# AVR16DU28 device description
Architecture: AVR8X; Family: AVR
Registers are 8-bit, read-write, reset 0x0 unless marked. A register's access mark holds for its fields unless they carry their own. Offsets are from the block's base; [hi:lo] are bit positions; {n}, {i} and the like mark numbered series; 'fields as' and 'values as' point back to an identical list.

## RSTCTRL — Reset controller
Instances: RSTCTRL 0x0040
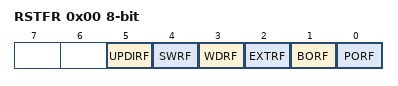
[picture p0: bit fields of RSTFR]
0x00 RSTFR — Reset Flags
  [5] UPDIRF — UPDI Reset flag
  [4] SWRF — Software Reset flag
  [3] WDRF — Watch dog Reset flag
  [2] EXTRF — External Reset flag
  [1] BORF — Brown out detector Reset flag
  [0] PORF — Power on Reset flag
0x01 SWRR — Software Reset
  [0] SWRST — Software reset enable

## RTC — Real-Time Counter
Instances: RTC 0x0140
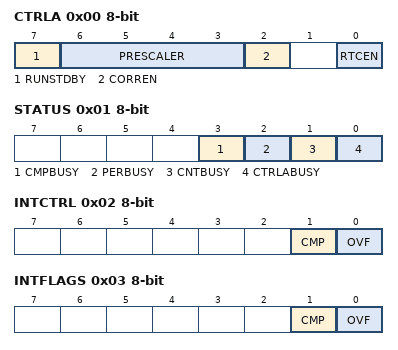
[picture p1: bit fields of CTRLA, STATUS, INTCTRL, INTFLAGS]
0x00 CTRLA — Control A
  [7] RUNSTDBY — Run In Standby
  [6:3] PRESCALER — Prescaling Factor
    0=DIV1 (RTC Clock / 1); 1=DIV2 (RTC Clock / 2); 2=DIV4 (RTC Clock / 4); 3=DIV8 (RTC Clock / 8); 4=DIV16 (RTC Clock / 16); 5=DIV32 (RTC Clock / 32); 6=DIV64 (RTC Clock / 64); 7=DIV128 (RTC Clock / 128); 8=DIV256 (RTC Clock / 256); 9=DIV512 (RTC Clock / 512); 10=DIV1024 (RTC Clock / 1024); 11=DIV2048 (RTC Clock / 2048); 12=DIV4096 (RTC Clock / 4096); 13=DIV8192 (RTC Clock / 8192); 14=DIV16384 (RTC Clock / 16384); 15=DIV32768 (RTC Clock / 32768)
  [2] CORREN — Correction enable
  [0] RTCEN — Enable
0x01 STATUS ro
  [3] CMPBUSY — Comparator Synchronization Busy Flag
  [2] PERBUSY — Period Synchronization Busy Flag
  [1] CNTBUSY — Count Synchronization Busy Flag
  [0] CTRLABUSY — CTRLA Synchronization Busy Flag
0x02 INTCTRL — Interrupt Control
  [1] CMP — Compare Match Interrupt enable
  [0] OVF — Overflow Interrupt enable
0x03 INTFLAGS — Interrupt Flags
  [1] CMP — Compare Match Interrupt
  [0] OVF — Overflow Interrupt Flag
0x04 TEMP reset not defined — Temporary
0x05 DBGCTRL — Debug control
  [0] DBGRUN — Run in debug
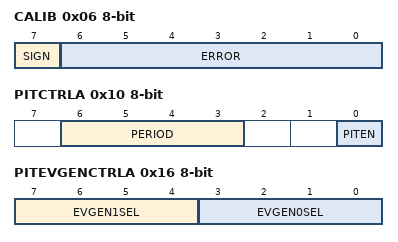
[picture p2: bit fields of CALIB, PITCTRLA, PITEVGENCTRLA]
0x06 CALIB — Calibration
  [7] SIGN — Error Correction Sign Bit
  [6:0] ERROR — Error Correction Value
0x07 CLKSEL — Clock Select
  [1:0] CLKSEL
    0=OSC32K (Internal 32.768 kHz Oscillator Divided by 32); 1=OSC1K (32.768 kHz Crystal Oscillator); 2=XOSC32K (Internal 32.768 kHz Oscillator); 3=EXTCLK (External Clock)
0x08 CNT 16-bit reset not defined — Counter
0x0A PER 16-bit reset 0xFFFF — Period
0x0C CMP 16-bit reset not defined — Compare
0x10 PITCTRLA — PIT Control A
  [6:3] PERIOD
    0=OFF; 1=CYC4 (RTC Clock Cycles 4); 2=CYC8 (RTC Clock Cycles 8); 3=CYC16 (RTC Clock Cycles 16); 4=CYC32 (RTC Clock Cycles 32); 5=CYC64 (RTC Clock Cycles 64); 6=CYC128 (RTC Clock Cycles 128); 7=CYC256 (RTC Clock Cycles 256); 8=CYC512 (RTC Clock Cycles 512); 9=CYC1024 (RTC Clock Cycles 1024); 10=CYC2048 (RTC Clock Cycles 2048); 11=CYC4096 (RTC Clock Cycles 4096); 12=CYC8192 (RTC Clock Cycles 8192); 13=CYC16384 (RTC Clock Cycles 16384); 14=CYC32768 (RTC Clock Cycles 32768)
  [0] PITEN — Enable
0x11 PITSTATUS ro
  [0] CTRLBUSY — CTRLA Synchronization Busy Flag
0x12 PITINTCTRL — PIT Interrupt Control
  [0] PI — Periodic Interrupt
0x13 PITINTFLAGS — PIT Interrupt Flags
  [0] PI — Periodic Interrupt
0x15 PITDBGCTRL — PIT Debug control
  [0] DBGRUN — Run in debug
0x16 PITEVGENCTRLA — PIT Event Generation Control A
  [7:4] EVGEN1SEL — Event Generation 1 Select
    0=OFF (No Event Generated); 1=DIV4 (CLK_RTC divided by 4); 2=DIV8 (CLK_RTC divided by 8); 3=DIV16 (CLK_RTC divided by 16); 4=DIV32 (CLK_RTC divided by 32); 5=DIV64 (CLK_RTC divided by 64); 6=DIV128 (CLK_RTC divided by 128); 7=DIV256 (CLK_RTC divided by 256); 8=DIV512 (CLK_RTC divided by 512); 9=DIV1024 (CLK_RTC divided by 1024); 10=DIV2048 (CLK_RTC divided by 2048); 11=DIV4096 (CLK_RTC divided by 4096); 12=DIV8192 (CLK_RTC divided by 8192); 13=DIV16384 (CLK_RTC divided by 16384); 14=DIV32768 (CLK_RTC divided by 32768)
  [3:0] EVGEN0SEL — Event Generation 0 Select
    values as EVGEN1SEL

## SIGROW — Signature row
Instances: SIGROW 0x1080
{0x0+i} DEVICEID{i} ro reset not defined (i=0..2) — Device ID Byte {i}
0x04 TEMPSENSE0 16-bit ro reset not defined — Temperature Calibration 0
0x06 TEMPSENSE1 16-bit ro reset not defined — Temperature Calibration 1
{0x10+i} SERNUM{i} ro reset not defined (i=0..5) — LOTNUM{i}
0x16 SERNUM6 ro reset not defined — RANDOM
0x17 SERNUM7 ro reset not defined — SCRIBE
0x18 SERNUM8 ro reset not defined — XPOS0
0x19 SERNUM9 ro reset not defined — XPOS1
0x1A SERNUM10 ro reset not defined — YPOS0
0x1B SERNUM11 ro reset not defined — YPOS1
{0x10+i} SERNUM{i} ro reset not defined (i=12..15) — RES{i-12}
